VERSION ""

NS_ :

BS_:

BU_: XMM_BOARD DOOR_ECU CLIMATE_ECU BMS_ECU

BO_ 528 DOOR_CONTROL: 8 XMM_BOARD
 SG_ DOOR_LOCK_CMD : 0|2@1+ (1,0) [0|3] "" DOOR_ECU
 SG_ DOOR_WINDOW_CMD : 2|2@1+ (1,0) [0|3] "" DOOR_ECU

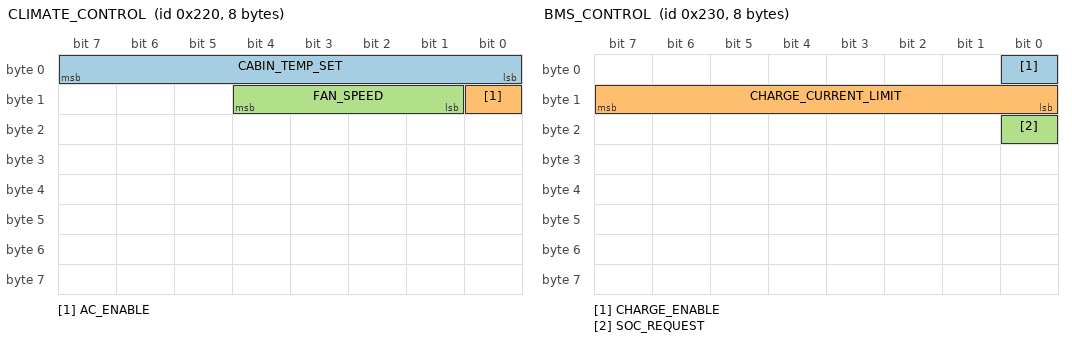
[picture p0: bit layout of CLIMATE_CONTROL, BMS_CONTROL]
BO_ 544 CLIMATE_CONTROL: 8 XMM_BOARD
 SG_ CABIN_TEMP_SET : 0|8@1+ (0.5,15) [15|35] "degC" CLIMATE_ECU
 SG_ AC_ENABLE : 8|1@1+ (1,0) [0|1] "" CLIMATE_ECU
 SG_ FAN_SPEED : 9|4@1+ (1,0) [0|10] "" CLIMATE_ECU

BO_ 560 BMS_CONTROL: 8 XMM_BOARD
 SG_ CHARGE_ENABLE : 0|1@1+ (1,0) [0|1] "" BMS_ECU
 SG_ CHARGE_CURRENT_LIMIT : 8|8@1+ (0.5,0) [0|100] "A" BMS_ECU
 SG_ SOC_REQUEST : 16|1@1+ (1,0) [0|1] "" BMS_ECU
